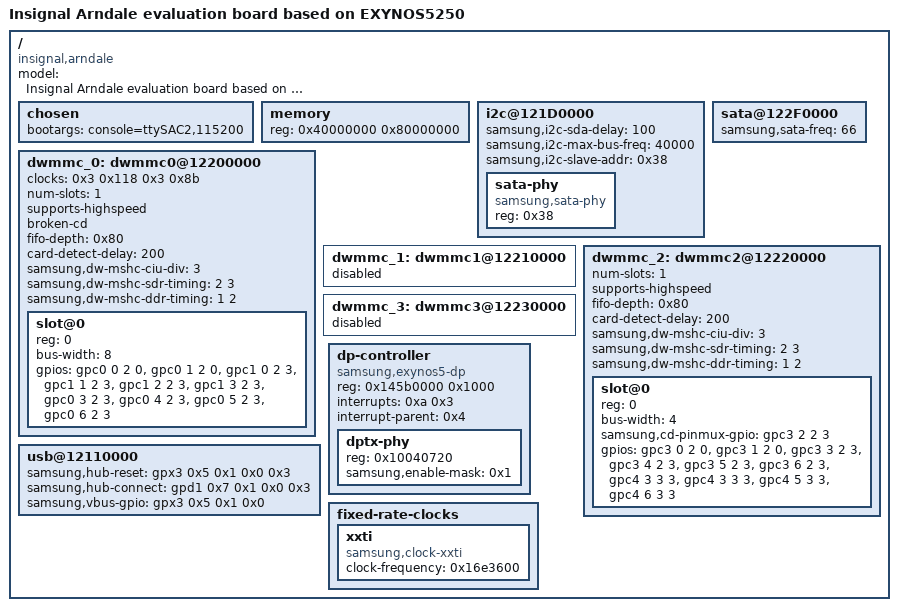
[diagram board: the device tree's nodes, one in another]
/*
 * SAMSUNG Arndale board device tree source
 *
 * This program is free software; you can redistribute it and/or modify
 * it under the terms of the GNU General Public License version 2 as
 * published by the Free Software Foundation.
*/
/dts-v1/;
/include/ "exynos5250.dtsi"

/ {
	model = "Insignal Arndale evaluation board based on EXYNOS5250";
	compatible = "insignal,arndale", "samsung,exynos5250";

	chosen {
		bootargs = "console=ttySAC2,115200";
	};


	memory {
		device_type = "memory";
		reg = <0x40000000 0x80000000>;
	};

	i2c@121D0000 {
		samsung,i2c-sda-delay = <100>;
		samsung,i2c-max-bus-freq = <40000>;
		samsung,i2c-slave-addr = <0x38>;

		sata-phy {
			compatible = "samsung,sata-phy";
			reg = <0x38>;
		};
	};

	sata@122F0000 {
		samsung,sata-freq = <66>;
	};

	dwmmc_0: dwmmc0@12200000 {
		clocks = <0x3 0x118 0x3 0x8b>;
		clock-names = "biu", "ciu";
		num-slots = <1>;
		supports-highspeed;
		broken-cd;
		fifo-depth = <0x80>;
		card-detect-delay = <200>;
		samsung,dw-mshc-ciu-div = <3>;
		samsung,dw-mshc-sdr-timing = <2 3>;
		samsung,dw-mshc-ddr-timing = <1 2>;

		slot@0 {
			reg = <0>;
			bus-width = <8>;
			gpios = <&gpc0 0 2 0 3>, <&gpc0 1 2 0 3>,
				<&gpc1 0 2 3 3>, <&gpc1 1 2 3 3>,
				<&gpc1 2 2 3 3>, <&gpc1 3 2 3 3>,
				<&gpc0 3 2 3 3>, <&gpc0 4 2 3 3>,
				<&gpc0 5 2 3 3>, <&gpc0 6 2 3 3>;
		};
	};

	dwmmc_1: dwmmc1@12210000 {
		status = "disabled";
	};

	dwmmc_2: dwmmc2@12220000 {
		num-slots = <1>;
		supports-highspeed;
		fifo-depth = <0x80>;
		card-detect-delay = <200>;
		samsung,dw-mshc-ciu-div = <3>;
		samsung,dw-mshc-sdr-timing = <2 3>;
		samsung,dw-mshc-ddr-timing = <1 2>;

		slot@0 {
			reg = <0>;
			bus-width = <4>;
			samsung,cd-pinmux-gpio = <&gpc3 2 2 3 3>;
			gpios = <&gpc3 0 2 0 3>, <&gpc3 1 2 0 3>,
				<&gpc3 3 2 3 3>, <&gpc3 4 2 3 3>,
				<&gpc3 5 2 3 3>, <&gpc3 6 2 3 3>,
				<&gpc4 3 3 3 3>, <&gpc4 3 3 3 3>,
				<&gpc4 5 3 3 3>, <&gpc4 6 3 3 3>;
		};
	};

	dwmmc_3: dwmmc3@12230000 {
		status = "disabled";
	};

	usb@12110000 {
		samsung,hub-reset = <&gpx3 0x5 0x1 0x0 0x3>;
		samsung,hub-connect = <&gpd1 0x7 0x1 0x0 0x3>;
		samsung,vbus-gpio = <&gpx3 0x5 0x1 0x0 0x3>;
	};


	dp-controller {
		compatible = "samsung,exynos5-dp";
		reg = <0x145b0000 0x1000>;
		interrupts = <0xa 0x3>;
		interrupt-parent = <0x4>;
		#address-cells = <0x1>;
		#size-cells = <0x0>;

		dptx-phy {
			reg = <0x10040720>;
			samsung,enable-mask = <0x1>;
		};
	};

	fixed-rate-clocks {

		xxti {
			compatible = "samsung,clock-xxti";
			clock-frequency = <0x16e3600>;
		};
	};

};
